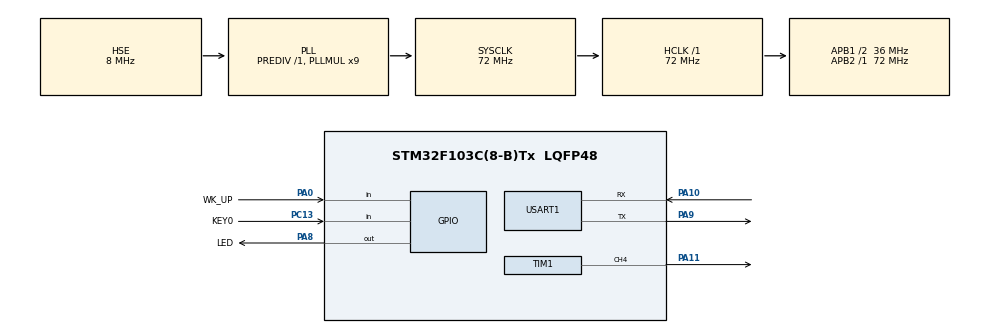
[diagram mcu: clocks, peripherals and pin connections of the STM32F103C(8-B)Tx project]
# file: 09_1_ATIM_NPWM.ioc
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Mcu.Family=STM32F1
Mcu.Name=STM32F103C(8-B)Tx
Mcu.Package=LQFP48
NVIC.PriorityGroup=NVIC_PRIORITYGROUP_2
NVIC.TIM1_UP_IRQn=true\:2\:1\:true\:false\:true\:true\:true\:true
NVIC.USART1_IRQn=true\:2\:0\:true\:false\:true\:true\:true\:true
PA0-WKUP.GPIO_Label=WK_UP
PA0-WKUP.GPIO_PuPd=GPIO_PULLDOWN
PA0-WKUP.Signal=GPIO_Input
PA10.Mode=Asynchronous
PA10.Signal=USART1_RX
PA11.Signal=S_TIM1_CH4
PA13.Mode=Serial_Wire
PA13.Signal=SYS_JTMS-SWDIO
PA14.Mode=Serial_Wire
PA14.Signal=SYS_JTCK-SWCLK
PA8.GPIO_Label=LED
PA8.GPIO_PuPd=GPIO_PULLUP
PA8.GPIO_Speed=GPIO_SPEED_FREQ_HIGH
PA8.PinState=GPIO_PIN_SET
PA8.Signal=GPIO_Output
PA9.Mode=Asynchronous
PA9.Signal=USART1_TX
PC13-TAMPER-RTC.GPIO_Label=KEY0
PC13-TAMPER-RTC.GPIO_PuPd=GPIO_PULLUP
PC13-TAMPER-RTC.Signal=GPIO_Input
PC14-OSC32_IN.Mode=LSE-External-Oscillator
PC14-OSC32_IN.Signal=RCC_OSC32_IN
PC15-OSC32_OUT.Mode=LSE-External-Oscillator
PC15-OSC32_OUT.Signal=RCC_OSC32_OUT
PD0-OSC_IN.Mode=HSE-External-Oscillator
PD0-OSC_IN.Signal=RCC_OSC_IN
PD1-OSC_OUT.Mode=HSE-External-Oscillator
PD1-OSC_OUT.Signal=RCC_OSC_OUT
ProjectManager.HeapSize=0x200
ProjectManager.StackSize=0x400
ProjectManager.TargetToolchain=STM32CubeIDE
RCC.AHBFreq_Value=72000000
RCC.APB1CLKDivider=RCC_HCLK_DIV2
RCC.APB1Freq_Value=36000000
RCC.APB1TimFreq_Value=72000000
RCC.APB2Freq_Value=72000000
RCC.APB2TimFreq_Value=72000000
RCC.HCLKFreq_Value=72000000
RCC.PLLMUL=RCC_PLL_MUL9
RCC.PLLSourceVirtual=RCC_PLLSOURCE_HSE
RCC.SYSCLKFreq_VALUE=72000000
RCC.SYSCLKSource=RCC_SYSCLKSOURCE_PLLCLK
RCC.USBFreq_Value=72000000
SH.S_TIM1_CH4.0=TIM1_CH4,PWM Generation4 CH4
TIM1.AutoReloadPreload=TIM_AUTORELOAD_PRELOAD_ENABLE
TIM1.Channel-PWM\ Generation4\ CH4=TIM_CHANNEL_4
TIM1.OC4Preload_PWM=DISABLE
TIM1.Period=5000 - 1
TIM1.Prescaler=7200 - 1
TIM1.Pulse-PWM\ Generation4\ CH4=2500
USART1.VirtualMode=VM_ASYNC
VP_TIM1_VS_ClockSourceINT.Mode=Internal
board=custom

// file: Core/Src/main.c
/**
 ****************************************************************************************************
 * @file        main.c
 * @author      ALIENTEK
 * @brief       Advanced-control timers output a specified number of PWM code
 * @license     Copyright (C) 2020-2032, ALIENTEK
 ****************************************************************************************************
 * @attention
 *
 * platform  	: ALIENTEK STM32F103 development board
 * website		: https://www.alientek.com
 * forum		: http://www.openedv.com/forum.php
 *
 * change logs	:
 * version		data		notes
 * V1.0			20240222	the first version
 *
 ****************************************************************************************************
 */

/* USER CODE BEGIN Header */

/* USER CODE END Header */
#include "main.h"
#include "tim.h"
#include "usart.h"
#include "gpio.h"

/* USER CODE BEGIN Includes */
#include "../../BSP/LED/led.h"
#include "../../BSP/KEY/key.h"
/* USER CODE END Includes */

void SystemClock_Config(void);

int main(void)
{
  /* USER CODE BEGIN 1 */
  uint8_t key = 0;
  uint8_t t = 0;
  /* USER CODE END 1 */

  /* MCU Configuration--------------------------------------------------------*/

  /* Reset of all peripherals, Initializes the Flash interface and the Systick. */
  HAL_Init();

  /* Configure the system clock */
  SystemClock_Config();

  /* Initialize all configured peripherals */
  MX_GPIO_Init();
  MX_USART1_UART_Init();
  MX_TIM1_Init();

  /* Infinite loop */
  /* USER CODE BEGIN WHILE */
  while (1)
  {
	  key = key_scan(0);             /* scan key */

	  if (key == KEY0_PRES)          /* KEY0 is pressed */
	  {
	  	 atim_timx_npwm_chy_set(5);  /* Control TIM1_CH4 output 5 PWM pulses. */
	  }

	  if (t > 20)                    /* Enter once in 200ms. */
	  {
	  	 t = 0;
	     LED_TOGGLE();               /* LED blinks to prompt the program to run */
	  }

	  t++;

	  HAL_Delay(10);                 /* delay 10ms */
    /* USER CODE END WHILE */

  }
}

void SystemClock_Config(void)
{
  RCC_OscInitTypeDef RCC_OscInitStruct = {0};
  RCC_ClkInitTypeDef RCC_ClkInitStruct = {0};

  /** Initializes the RCC Oscillators according to the specified parameters
  * in the RCC_OscInitTypeDef structure.
  */
  RCC_OscInitStruct.OscillatorType = RCC_OSCILLATORTYPE_HSE;
  RCC_OscInitStruct.HSEState = RCC_HSE_ON;
  RCC_OscInitStruct.HSEPredivValue = RCC_HSE_PREDIV_DIV1;
  RCC_OscInitStruct.HSIState = RCC_HSI_ON;
  RCC_OscInitStruct.PLL.PLLState = RCC_PLL_ON;
  RCC_OscInitStruct.PLL.PLLSource = RCC_PLLSOURCE_HSE;
  RCC_OscInitStruct.PLL.PLLMUL = RCC_PLL_MUL9;
  if (HAL_RCC_OscConfig(&RCC_OscInitStruct) != HAL_OK)
  {
    Error_Handler();
  }

  /** Initializes the CPU, AHB and APB buses clocks
  */
  RCC_ClkInitStruct.ClockType = RCC_CLOCKTYPE_HCLK|RCC_CLOCKTYPE_SYSCLK
                              |RCC_CLOCKTYPE_PCLK1|RCC_CLOCKTYPE_PCLK2;
  RCC_ClkInitStruct.SYSCLKSource = RCC_SYSCLKSOURCE_PLLCLK;
  RCC_ClkInitStruct.AHBCLKDivider = RCC_SYSCLK_DIV1;
  RCC_ClkInitStruct.APB1CLKDivider = RCC_HCLK_DIV2;
  RCC_ClkInitStruct.APB2CLKDivider = RCC_HCLK_DIV1;

  if (HAL_RCC_ClockConfig(&RCC_ClkInitStruct, FLASH_LATENCY_2) != HAL_OK)
  {
    Error_Handler();
  }
}

void Error_Handler(void)
{
  __disable_irq();
  while (1)
  {
  }
}
